# DPWM0 register map
Vendor: Texas Instruments
Peripheral module from a debugger description file (folder UCD3138R032RSM).
Registers are 32-bit, access per field, no defined reset value unless marked. A register's access mark holds for its fields unless they carry their own. Offsets are as the file gives them; lines under a group give offsets from that group; [hi:lo] are bit positions; {n}, {i} and the like mark numbered series; 'fields as' and 'values as' point back to an identical list; <NAME> marks a mode.

## DPWM0 — This is the MMR space for 1 instance of the DPWM
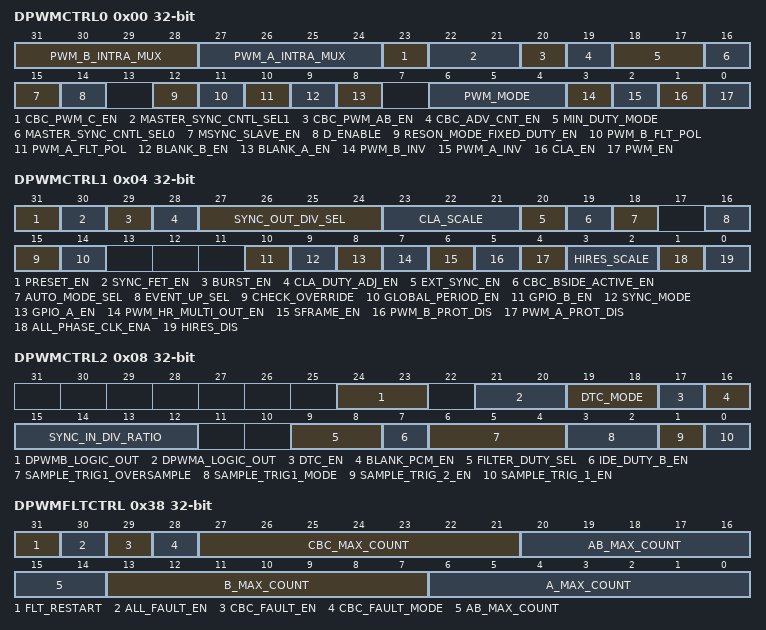
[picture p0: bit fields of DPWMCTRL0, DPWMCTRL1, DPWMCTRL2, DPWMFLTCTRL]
0x00 DPWMCTRL0 — DPWM Control Register 0
  [31:28] PWM_B_INTRA_MUX rw — Interchanges DPWM signals post edge generation
    8=n_3_C (Pass-through (DPWM n+3)C); 7=n_2_C (Pass-through (DPWM n+2)C); 6=n_1_C (Pass-through (DPWM n+1)C); 5=n_1_B (Pass-through (DPWM n+1)B); 4=n_1_A (Pass-through (DPWM n+1)A); 3=Crossover, this module; 2=PWM-C (PWM-C, this module); 1=Edge-gen output, this module; 0=Pass-through (Default)
  [27:24] PWM_A_INTRA_MUX rw — Combines DPWM signals are prior to HR module
    values as PWM_B_INTRA_MUX
  [23] CBC_PWM_C_EN rw — Sets if Fault CBC changes output waveform for PWM-C
    1=affected (PWM-C affected by Fault CBC); 0=unaffected (PWM-C unaffected by Fault CBC (Default))
  [22:21] MASTER_SYNC_CNTL_SEL1 rw — Master sync signal output selection when MASTER_SYNC_CNTL_SEL0=1
    2=CLA_DUTY_by_3 (Master sync output generated at CLA_DUTY/3 value); 1=CLA_DUTY_by_2 (Master sync output generated at CLA_DUTY/2 value); 0=CLA_PERIOD (Master sync output generated at CLA_PERIOD value (Default))
  [20] CBC_PWM_AB_EN rw — Sets if Fault CBC changes output waveform for PWM-A and PWM-B
    1=effected (PWM-A and PWM-B affected by Fault CBC); 0=unaffected (PWM-A and PWM-B unaffected by Fault CBC (Default))
  [19] CBC_ADV_CNT_EN rw — Selects cycle-by-cycle of operation
    1=effected (Normal Mode 1 = CBC enabled Multi and Resonant Modes 1 = PWM-A and PWM-B operate pulse matching enabled); 0=unaffected (Normal Mode 0 = CBC disabled (Default) Multi and Resonant Modes 0 = PWM-A and PWM-B operate independently (Default))
  [18:17] MIN_DUTY_MODE rw — Minimum Duty Cycle Mode
    2=calmped (= CLA value is clamped to MIN_DUTY_LOW register value when input value is less than MIN_DUTY_LOW); 1=calmped_zero (CLA value is clamped to zero when below input value is less than MIN_DUTY_LOW); 0=default (Suppression of minimum duty cycles is disabled (Default))
  [16] MASTER_SYNC_CNTL_SEL0 rw — Configures master sync location
    1=MASTER_SYNC_CNTL_SEL1 (Master Sync output controlled by MASTER_SYNC_CNTL_SEL1 bits); 0=Phase_Trigger_Register (Master Sync output controlled by Phase Trigger Register (Default))
  [15] MSYNC_SLAVE_EN rw — Multi-Sync Slave Mode Control
    1=Enable Multi-Sync Slave Mode, current channel will be slaved from corresponding channel; 0=default (PWM not synchronized to another PWM channel (Default))
  [14] D_ENABLE rw — Converts CLA duty value to DPWM as period-CLA duty value
    1=enable (Value used for event calculations is period minus CLA duty value); 0=default (Value used for event calculations if CLA Duty (Default))
  [12] RESON_MODE_FIXED_DUTY_EN rw — Configures how duty cycle is controlled in Resonance Mode
    1=SWITCH_HIGH (Resonant mode duty cycle set by Auto Switch High Register.); 0=default (Resonant mode duty cycle set by Filter duty (Default))
  [11] PWM_B_FLT_POL rw — Sets the fault output polarity during a disable condition (i.e. fault or module disabled)
    1=high (PWM B fault output polarity is set to high); 0=low (PWM B fault output polarity is set to low (Default))
  [10] PWM_A_FLT_POL rw — Sets the fault output polarity during a disable condition (i.e. fault or module disabled)
    1=high (PWM A fault output polarity is set to high); 0=low (PWM A fault output polarity is set to low (Default))
  [9] BLANK_B_EN rw — Comparator Blanking Window B Enable
    1=enabled (Comparator Blanking Window for PWM-B Enabled); 0=disabled (Comparator Blanking Window for PWM-B Disabled (Default))
  [8] BLANK_A_EN rw — Comparator Blanking Window A Enable
    1=enabled (Comparator Blanking Window for PWM-A Enabled); 0=disabled (Comparator Blanking Window for PWM-A Disabled (Default))
  [6:4] PWM_MODE rw — DPWM Mode
    4=Leading_mode; 2=MULTI_mode (Multi-Output Mode (Default)); 3=Triangular Mode; 1=Resonant Mode; 0=Normal Mode
  [3] PWM_B_INV rw — PWM B Output Polarity Control
    1=inverted (Inverts PWM B output); 0=Non-inverted PWM B output (Default)
  [2] PWM_A_INV rw — PWM A Output Polarity Control
    1=inverted (Inverts PWM A output); 0=Non-inverted PWM A output (Default)
  [1] CLA_EN rw — CLA Processing Enable
    1=Enable CLA input (Default); 0=Generate PWM waveforms from PWM Register values
  [0] PWM_EN rw — PWM Processing Enable
    1=Enable PWM operation; 0=Disable PWM module, outputs zero (Default)
0x04 DPWMCTRL1 — DPWM Control Register 1
  [31] PRESET_EN rw — Counter Preset Enable
    1=preset (Counter preset to Preset Count Value upon detection of sync); 0=reset (Counter reset to 0 upon detection of sync (Default))
  [30] SYNC_FET_EN rw — Counter Preset Enable
    1=enable (SyncFET Mode Enabled); 0=disable (SyncFET Mode Disabled (Default))
  [29] BURST_EN rw — Burst (Light Load) Mode Detection Enable
    1=enable (Burst Mode (Light Load) Detection enabled); 0=disable (Burst Mode (Light Load) Detection disabled (Default))
  [28] CLA_DUTY_ADJ_EN rw — Enables CLA Duty Adjust from Current/Flux Balancing
    1=enable (CLA Duty Adjust enabled); 0=disable (CLA Duty Adjust not enabled (Default))
  [27:24] SYNC_OUT_DIV_SEL rw — Sets the divider for generating the Sync Out pulse.Sync Out generated once every (n+1)switching cycles
    1=enable (Sync Out generated once every 2 switching cycles); 0=disable (Sync Out generated on every switching cycle (Default))
  [23:21] CLA_SCALE rw — Scaling for CLA Input Data
    6=CLA (CLA Value); 6=D_8 (CLA Value divided by 8); 5=M_8 (CLA Value multiplied by 8); 4=D_4 (CLA Value divided by 4); 3=M_4 (CLA Value multiplied by 4); 2=D_2 (CLA Value divided by 2); 1=M_2 (CLA Value multiplied by 2); 0=default (CLA Value (Default))
  [20] EXT_SYNC_EN rw — Slave DPWM to external sync
    1=sync (Slave DPWM to external sync); 0=not_sync (DPWM not synchronized to external sync (Default))
  [19] CBC_BSIDE_ACTIVE_EN rw — Sets if CBC responds to Fault CBC when PWM-B is active, only available in Multi and Reson modes
    1=sync (Response to Fault CBC when PWM-A or PWM-B active); 0=default (Response to Fault CBC when PWM-A active (Default))
  [18] AUTO_MODE_SEL rw — Auto Switching Mode Selec
    1=enabled (Auto Switching Mode enabled); 0=disabled (Auto Switching Mode disabled (Default))
  [16] EVENT_UP_SEL rw — Update End Period Mode
    0=anytime_update (Events updated anytime (Default)); 1=End_of_period_update (Events updated at End of Period)
  [15] CHECK_OVERRIDE rw — PWM Check Override
    1=b (Overrides checking for invalid configurations and turns off PWM mathematical checking functions (Default)); 0=a (DPWM checks mathematical settings within module, correct placement of Event settings/period settings. Invalid configurations are not allowed)
  [14] GLOBAL_PERIOD_EN rw — PWM Check Override
    1=GLOBAL (Event calculations use Global Period register); 0=DPWM (Event calculations use DPWM Period register (Default))
  [10] GPIO_B_EN rw — Enables GPIO mode for PWM B output
    1=GPIO (PWM B in GPIO mode); 0=DPWM (PWM B in DPWM mode (Default))
  [9] SYNC_MODE rw — Selects dynamic period adjustment based on sync input pulses
    1=Enabled (DPWM period register is updated dynamically based on SYNC input pulse width and DPWMPRD_SYNC_ADJ); 0=Disabled (DPWM period register is fixed and not updated dynamically (Default))
  [8] GPIO_A_EN rw — Enables GPIO mode for PWM A output
    1=GPIO (PWM A in GPIO mode); 0=DPWM (PWM A in DPWM mode (Default))
  [7] PWM_HR_MULTI_OUT_EN rw — Control bit for Hi-Res Block
    1=Enabled; 0=Disabled (Default)
  [6] SFRAME_EN rw — PWM Single Step Frame Mode Enable
    1== Enable Single Step Frame Mode. One EADC sample is requested, CLA then Filters, then one PWM duty cycle performed, then wait on Single Frame Trigger toggle before advancing to next frame.; 0=Disable Single Frame Mode (Default)
  [5] PWM_B_PROT_DIS rw — PWM B Asynchronous Protection Disable
    1=Disables asynchronous protection from turning off PWM B Output; 0=enable (Allows asynchronous protection to turn off PWM B Output (Default))
  [4] PWM_A_PROT_DIS rw — PWM A Asynchronous Protection Disable
    1=Disables asynchronous protection from turning off PWM A Output; 0=enable (Allows asynchronous protection to turn off PWM A Output (Default))
  [3:2] HIRES_SCALE rw — Determines resolution of high resolution steps
    3=PCLK_2 (Resolution of 2 phases. Full Resolution enabled.Resolution step = PCLK/2); 2=PCLK_4 (Resolution of 4 phases. Full Resolution enabled.Resolution step = PCLK/4); 1=PCLK_8 (Resolution of 8 phases. Full Resolution enabled.Resolution step = PCLK/8); 0=PCLK_16 (Resolution of 16 phases. Full Resolution enabled.Resolution step = PCLK/16)
  [1] ALL_PHASE_CLK_ENA rw — High Speed Oscillator Phase Enable
    1=enable_all (Enables all phases of high resolution clock from oscillator (Default)); 0=enable_required (Enables only required phases of clock when needed)
  [0] HIRES_DIS rw — PWM High Resolution Disable
    1=enable_all (Disable High Resolution logic); 0=enable_required (Enable High Resolution logic (Default))
0x08 DPWMCTRL2 — DPWM Control Register 2
  [24:23] DPWMB_LOGIC_OUT rw — Selection of final logic gating for DPWMB signal
    0=Mode0 (Passthrough (default)); 1=Mode1 (DPWMA (OR) DPWMB); 2=Mode2 (DPWMA (AND) DPWMB); 3=Mode3 (DPWM (XOR) DPWMB)
  [21:20] DPWMA_LOGIC_OUT rw — Selection of final logic gating for DPWMA signal
    values as DPWMB_LOGIC_OUT
  [19:18] DTC_MODE rw — DTC Mode Select
    0=DTC_phase_A (Only DTC phase adjust A utilized in edge adjustments (Default)); 1=DTC_phase_B (Only DTC phase adjust B utilized in edge adjustments); 2=DTC_phase_AB (Both DTC phase adjust A and B utilized in edge adjustments)
  [17] DTC_EN rw — Enables Dead Time Compensation Mode
    0=Disabled (Default); 1=Enabled
  [16] BLANK_PCM_EN rw — Comparator Blanking Window B Enable for PCM
    0=Disabled (Comparator Blanking A Window Disabled (Default)); 1=Enabled (Comparator Blanking A Window for PWM-B Enabled)
  [15:12] SYNC_IN_DIV_RATIO rw — Sets the number of syncs to be masked before a resync
  [9:8] FILTER_DUTY_SEL rw — Sets which register is sent to the Resonant Duty input of the Filter. Settings of 0 and 1 enable the 16 bit signed value of the Resonant Duty register to be added to the Filter Period value for period adjustment in resonant mode.
    0=PWM (PWM Period Register (Default)); 2=PWM Resonant Duty Register (Bits 13:0); 1=Event 2
  [7] IDE_DUTY_B_EN rw — IDE Duty Cycle Side B Enable
    1=enabled; 0== Disabled (Default)
  [6:4] SAMPLE_TRIG1_OVERSAMPLE rw — Oversample Select for Sample Trigger 1
    3=Eight (Trigger a EADC Sample at PWM Sample Trig Register value, and at PWM Sample Trig Register value by 7/8 and at PWM Sample Trig Register value by 6/8 and at PWM Sample Trig Register value by 5/8 and at PWM Sample Trig Register value by 4/8 and at PWM Sample Trig Register value by 3/8 and at PWM Sample Trig Register value by 2/8 and at PWM Sample Trig Register value by 1/8); 2=Four (Trigger a EADC Sample at PWM Sample Trig Register value, and at PWM Sample Trig Register value by 3/4 and at PWM Sample Trig Register value by 2/4 and at PWM Sample Trig Register value by 1/4); 1=Two (Trigger an EADC Sample at PWM Sample Trig Register value and at PWM Sample Trig Register value divided by 2); 0=default (Trigger an EADC Sample at PWM Sample Trig Register value (Default)); 4=Sixteen (Trigger a EADC Sample at PWM Sample Trig Register value, and at PWM Sample Trig Register value by 15/16 and at PWM Sample Trig Register value by 14/16 and at PWM Sample Trig Register value by 13/16 and at PWM Sample Trig Register value by 12/16 and at PWM Sample Trig Register value by 11/16 and at PWM Sample Trig Register value by 10/16 and at PWM Sample Trig Register value by 9/16 and at PWM Sample Trig Register value by 8/16 and at PWM Sample Trig Register value by 7/16 and at PWM Sample Trig Register value by 6/16 and at PWM Sample Trig Register value by 5/16 and at PWM Sample Trig Register value by 4/16 and at PWM Sample Trig Register value by 3/16 and at PWM Sample Trig Register value by 2/16 and at PWM Sample Trig Register value by 1/16); 5=ThirtyTwo (Trigger a EADC Sample at PWM Sample Trig Register value, and at PWM Sample Trig Register value by 31/32 and at PWM Sample Trig Register value by 30/32 and at PWM Sample Trig Register value by 29/32 and at PWM Sample Trig Register value by 28/32 and at PWM Sample Trig Register value by 27/32 and at PWM Sample Trig Register value by 26/32 and at PWM Sample Trig Register value by 25/32 and at PWM Sample Trig Register value by 24/32 and at PWM Sample Trig Register value by 23/32 and at PWM Sample Trig Register value by 22/32 and at PWM Sample Trig Register value by 21/32 and at PWM Sample Trig Register value by 20/32 and at PWM Sample Trig Register value by 19/32 and at PWM Sample Trig Register value by 18/32 and at PWM Sample Trig Register value by 17/32 and at PWM Sample Trig Register value by 16/32 and at PWM Sample Trig Register value by 15/32 and at PWM Sample Trig Register value by 14/32 and at PWM Sample Trig Register value by 13/32 and at PWM Sample Trig Register value by 12/32 and at PWM Sample Trig Register value by 11/32 and at PWM Sample Trig Register value by 10/32 and at PWM Sample Trig Register value by 9/32 and at PWM Sample Trig Register value by 8/32 and at PWM Sample Trig Register value by 7/32 and at PWM Sample Trig Register value by 6/32 and at PWM Sample Trig Register value by 5/32 and at PWM Sample Trig Register value by 4/32 and at PWM Sample Trig Register value by 3/32 and at PWM Sample Trig Register value by 2/32 and at PWM Sample Trig Register value by 1/32)
  [3:2] SAMPLE_TRIG1_MODE rw — Mode select for Sample Trigger 1
    3=mode2 (Trigger value is adaptive based on previous CBC location + Adaptive Offset); 2=mode1 (Trigger value is adaptive midpoint (EV1+CLA_DUTY/2 + Adaptive Offset) and uses previous CLA value at update event); 1=mode0 (Trigger value is adaptive midpoint (EV1+CLA_DUTY/2 + Adaptive Offset) and uses current CLA value at update event); 0=default (Trigger value is set using PWM Sample Trig Register value (Default))
  [1] SAMPLE_TRIG_2_EN rw — Sample Trigger 2 Enable
    1=enabled (Enable Sample Trigger 2); 0=disabled (Sample Trigger 2 Enable)
  [0] SAMPLE_TRIG_1_EN rw — Sample Trigger 1 Enable
    1=enabled (Enable Sample Trigger 1); 0=disabled (Sample Trigger 1 Enable)
0x0C DPWMPRD — DPWM Period Register
  [17:4] Period rw — PWM Period. Low resolution register, last 4 bits are read-only.
0x10 DPWMEV1 — DPWM Event 1 Register
  [17:4] EVENT1 rw — Configures the location of Event 1. Low resolution register, last 4 bits are unused
0x14 DPWMEV2 — DPWM Event 2 Register
  [17:0] EVENT2 rw — Configures the location of Event 2. Value equals number of PCLK clock periods in Bits 17:4 and number of high resolution clock phases of PCL in Bits 3:0 (dependent on Bits 3:2 of DPWM Control Register 2).
0x18 DPWMEV3 — DPWM Event 3 Register
  [17:0] EVENT3 rw — Configures the location of Event 3. Value equals number of PCLK clock periods in Bits 17:4 and number of high resolution clock phases of PCL in Bits 3:0
0x1C DPWMEV4 — DPWM Event 4 Register
  [17:0] EVENT4 rw — Configures the location of Event 4. Value equals number of PCLK clock periods in Bits 17:4 and number of high resolution clock phases of PCL in Bits 3:0
0x20 DPWMSAMPTRIG1 — DPWM Sample Trigger 1 Register
  [17:6] SAMPLE_TRIGGER rw — Configures the location of the sample trigger within a PWM period. Value equals the number of PCLK clock periods. Enables start of conversion for EADC. Low resolution register, last 6 bits are read-only
0x24 DPWMSAMPTRIG2 — DPWM Sample Trigger 2 Register
  [17:6] SAMPLE_TRIGGER rw — Configures the location of the sample trigger within a PWM period. Value equals the number of PCLK clock periods. Enables start of conversion for EADC. Low resolution register, last 6 bits are read-only.
0x28 DPWMPHASETRIG — DPWM Phase Trigger Register
  [17:4] PHASE_TRIGGER rw — Configures the phase trigger delay within multi-output mode. Value equals the number of PCLK clock periods. Low resolution register, last 4 bits are read-only
0x2C DPWMCYCADJA rw — DPWM Cycle Adjust A Register
  [15:0] CYCLE_ADJUST_A — Adjusts PWM A output signal. 16-bit signed number allows output signal to be delayed or sped up
0x30 DPWMCYCADJB rw — DPWM Cycle Adjust B Register
  [15:0] CYCLE_ADJUST_B — Adjusts PWM B output signal. 16-bit signed number allows output signal to be delayed or sped up
0x34 DPWMRESDUTY rw — DPWM Resonant Duty Register
  [13:0] RESONANT_DUTY — Controls the DPWM duty. 14-bit signed number is used as a Filter Output Multiplier in Resonant Mode
0x38 DPWMFLTCTRL rw — DPWM Fault Control Register
  [31] FLT_RESTART — Enables DPWM after Fault.
    1=enable (All DPWM Fault Modules enabled); 0=disable (All DPWM Fault Modules disabled (Default))
  [30] ALL_FAULT_EN — DPWM Fault Module enable
    1=enabled (All DPWM Fault Modules enabled); 0=diasbled (All DPWM Fault Modules disabled (Default))
  [29] CBC_FAULT_EN — Cycle by cycle Fault Enable
    1=enabled (DPWM to shut off as with any other fault); 0=shorten (Cycle by cycle just shortens DPWM pulses)
  [28] CBC_FAULT_MODE
    1=CBC_output (CBC Fault input set to output of CBC module); 0=raw_CBC (CBC Fault input set to raw CBC fault)
  [27:21] CBC_MAX_COUNT — ycle-by-Cycle Fault Count, sets the number of received sequential faults on Cycle by-Cycle Fault input before asserting the fault
  [20:14] AB_MAX_COUNT — Fault AB Count, sets the number of received sequential faults on Fault AB input before asserting the fault
  [13:7] B_MAX_COUNT — Fault B Count, sets the number of received sequential faults on Fault A input before asserting the fault
  [6:0] A_MAX_COUNT — Fault A Count, sets the number of received sequential faults on Fault A input before asserting the fault
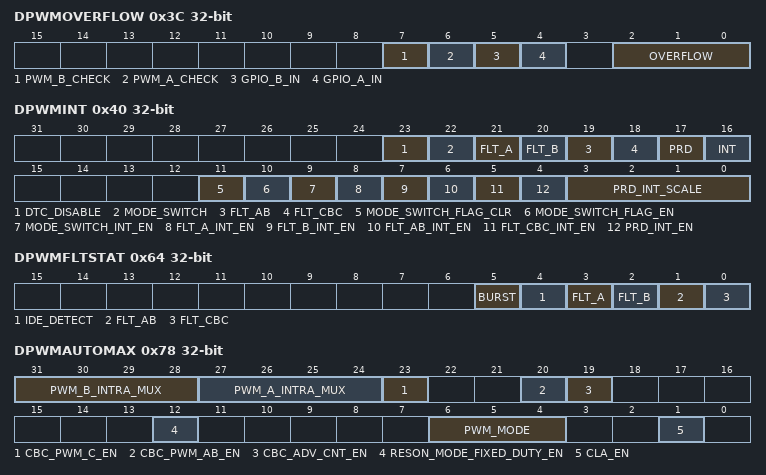
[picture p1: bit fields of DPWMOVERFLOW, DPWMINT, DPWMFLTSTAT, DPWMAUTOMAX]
0x3C DPWMOVERFLOW ro
  [7] PWM_B_CHECK — Value of PWM B internal check
    1=Failed checks (override required to enable output); 0=Passed checks
  [6] PWM_A_CHECK — Value of PWM A internal check
    values as PWM_B_CHECK
  [5] GPIO_B_IN — Value of PWM B input
    1=High signal on PWM B; 0=low (Low signal on PWM B)
  [4] GPIO_A_IN — Value of PWM A input
    1=High signal on PWM A; 0=low (Low signal on PWM A)
  [2:0] OVERFLOW — OVERFLOW[2] - CLA Event 4 Overflow Status 0 = PWM Event 4 has not overflowed 1 = Overflow condition found on PWM Event 4 OVERFLOW[1] - CLA Event 3 Overflow Status 0 = CLA Event 3 has not overflowed 1 = Overflow condition found on CLA Event 3 OVERFLOW[0] - CLA Event 2 Overflow Status 0 = CLA Event 2 has not overflowed 1 = Overflow condition found on CLA Event 2
0x40 DPWMINT — DPWM Interrupt Register
  [23] DTC_DISABLE ro — DTC Disabled Flag
    1=Set (Flag is set); 0=Not_asserted (Flag is not asserted)
  [22] MODE_SWITCH ro — Mode Switching Flag
    1=asserted (Flag is set); 0=not_asserted (Flag is not asserted)
  [21] FLT_A ro — Fault A Flag
    values as MODE_SWITCH
  [20] FLT_B ro — Fault B Flag
    values as MODE_SWITCH
  [19] FLT_AB ro — Fault AB Flag
    values as MODE_SWITCH
  [18] FLT_CBC ro — Fault Cycle-by-Cycle Flag
    values as MODE_SWITCH
  [17] PRD ro — PWM Period Interrupt Flag
    values as MODE_SWITCH
  [16] INT ro — Interrupt Out
    values as MODE_SWITCH
  [11] MODE_SWITCH_FLAG_CLR rw — Mode Switching Flag Clear
    1=Rising edge. 0-1 clears MODE_SWITCH bit; 0=default
  [10] MODE_SWITCH_FLAG_EN rw — Mode Switching Flag Enable
    1=Enables generation of flag for Mode Switching; 0=Disables generation of flag for Mode Switching (Default)
  [9] MODE_SWITCH_INT_EN rw — Mode Switching Interrupt Enable
    1=enable (Interrupt is enabled); 0=disable (Interrupt is not enabled (Default))
  [8] FLT_A_INT_EN rw — Fault A Flag Interrupt Enable
    values as MODE_SWITCH_INT_EN
  [7] FLT_B_INT_EN rw — Fault B Flag Interrupt Enable
    values as MODE_SWITCH_INT_EN
  [6] FLT_AB_INT_EN rw — Fault AB Flag Interrupt Enable
    values as MODE_SWITCH_INT_EN
  [5] FLT_CBC_INT_EN rw — Fault Cycle-by-Cycle Flag Interrupt Enable
    values as MODE_SWITCH_INT_EN
  [4] PRD_INT_EN rw — PWM Period Interrupt Enable
    1=Enables generation of periodic PWM interrupt; 0=Disables generation of periodic PWM interrupt (Default)
  [3:0] PRD_INT_SCALE rw — PWM Period Interrupt Enable
    15=switching_256 (Period Interrupt generated once every 256 switching cycle); 14=switching_224 (Period Interrupt generated once every 224 switching cycle); 13=switching_192 (Period Interrupt generated once every 192 switching cycle); 12=switching_160 (Period Interrupt generated once every 160 switching cycle); 11=switching_128 (Period Interrupt generated once every 128 switching cycle); 10=switching_96 (Period Interrupt generated once every 128 switching cycle); 9=switching_80 (Period Interrupt generated once every 80 switching cycle); 8=switching_64 (Period Interrupt generated once every 64 switching cycle); 7=switching_48 (Period Interrupt generated once every 48 switching cycle); 6=switching_32 (Period Interrupt generated once every 32 switching cycle); 5=switching_16 (Period Interrupt generated once every 16 switching cycle); 4=switching_8 (Period Interrupt generated once every 8 switching cycle); 3=switching_6 (Period Interrupt generated once every 6 switching cycle); 2=switching_4 (Period Interrupt generated once every 4 switching cycle); 1=switching_2 (Period Interrupt generated once every 2 switching cycle); 0=switching_1 (Period Interrupt generated every switching cycle (Default))
0x44 DPWMCNTPRE — DPWM Counter Preset Register
  [17:4] PRESET rw — Counter preset value, counter reset to this value upon detection of sync when PRESET_EN bit in DPWMCTRL2 is enabled. Low resolution register, last 4 bits are read-only.
0x48 DPWMBLKABEG — DPWM Blanking A Begin Register
  [17:4] BLANK_A_BEGIN rw — Configures start of Comparator Blanking Window A. Low resolution register, last 4 bits are read-only
0x4C DPWMBLKAEND — DPWM Blanking A End Register
  [17:4] BLANK_A_END rw — Configures end of Comparator Blanking Window A. Low resolution register, last 4 bits are read-only.
0x50 DPWMBLKBBEG — DPWM Blanking B Begin Register
  [17:4] BLANK_B_BEGIN rw — Configures start of Comparator Blanking Window B. Low resolution register, last 4 bits are read-only. Can also define the start of the DPWMC pulse.
0x54 DPWMBLKBEND — DPWM Blanking B End Register
  [17:4] BLANK_B_END rw — Configures end of Comparator Blanking Window B. Low resolution register, last 4 bits are read-only. Can also define the end of the DPWMC pulse
0x58 DPWMMINDUTYHI — DPWM Minimum Duty Cycle High Register
  [17:4] MIN_DUTY_HIGH rw — Configures upper threshold for minimum duty cycle logic. Low resolution register, last 4 bits are read-only
0x5C DPWMMINDUTYLO — DPWM Minimum Duty Cycle Low Register
  [17:4] MIN_DUTY_LOW rw — Configures lower threshold for minimum duty cycle logic. Low resolution register, last 4 bits are read-only
0x60 DPWMADAPTIVE rw — DPWM Adaptive Sample Register
  [11:0] ADAPT_SAMP — Configures Adaptive Sample Adjust
0x64 DPWMFLTSTAT ro — DPWM Fault Status
  [5] BURST — Burst Mode Detection Status
    1=asserted (Burst Mode Detection is set); 0=not_asserted (Burst Mode Detection is not asserted)
  [4] IDE_DETECT — IDE Detection Status (from Analog Comparators)
    1=asserted (IDE Detection is se); 0=not_asserted (IDE Detection is not asserted)
  [3] FLT_A — Fault A Detection Status
    1=asserted (Fault A Detection is set); 0=not_asserted (Fault A Detection is not asserted)
  [2] FLT_B — Fault B Detection Status
    1=asserted (Fault B Detection is set); 0=not_asserted (Fault B Detection is not asserted)
  [1] FLT_AB — Fault AB Detection Status
    1=asserted (Fault AB Detection is set); 0=not_asserted (Fault AB Detection is not asserted)
  [0] FLT_CBC — Current Limit Detection Status
    1=asserted (Current Limit Detection is set); 0=not_asserted (Current Limit Detection is not asserted)
0x68 DPWMAUTOSWHIUPTHRESH — DPWM Auto Switch High Upper Thresh Register
  [17:4] AUTO_SWITCH_HIGH_UPPER rw — Configures upper threshold for Auto Switch Mode High operation. Mode switching does not occur between Auto Switch High Upper and Auto Switch High Lower thresholds. Low resolution register, last 4 bits are read-only
0x6C DPWMAUTOSWHILOWTHRESH — DPWM Auto Switch High Upper Thresh Register
  [17:4] AUTO_SWITCH_HIGH_LOWER rw — Configures lower threshold for Auto Switch Mode High operation. Mode switching does not occur between Auto Switch High Upper and Auto Switch High Lower thresholds. Low resolution register, last 4 bits are read-only.
0x70 DPWMAUTOSWLOUPTHRESH — DPWM Auto Switch Low Upper Thresh Register
  [17:4] AUTO_SWITCH_LOW_UPPER rw — Configures UPPER threshold for Auto Switch Mode High operation. Mode switching does not occur between Auto Switch Low Upper and Auto Switch Low Lower thresholds. Low resolution register, last 4 bits are read-only.
0x74 DPWMAUTOSWLOLOWTHRESH — DPWM Auto Switch Low Lower Thresh Register
  [17:4] AUTO_SWITCH_LOW_LOWER rw — Configures lower threshold for Auto Switch Mode Low operation. Mode switching does not occur between Auto Switch Low Upper and Auto Switch Low Lower thresholds. Low resolution register, last 4 bits are read-only
0x78 DPWMAUTOMAX — DPWM Auto Config Max Register
  [31:28] PWM_B_INTRA_MUX rw — Interchanges DPWM signals post edge generation
    8=N_3_C (Pass-through (DPWM n+3)C); 7=N_2_C (Pass-through (DPWM n+2)C); 6=N_1_C (Pass-through (DPWM n+1)C); 5=N_1_B (Pass-through (DPWM n+1)B); 4=N_1_A (Pass-through (DPWM n+1)A); 3=Crossover, this module; 2=PWM_C (PWM-C, this module); 1=Edge-gen output, this module; 0=default (Pass-through (Default))
  [27:24] PWM_A_INTRA_MUX rw — Combines DPWM signals are prior to HR module
    values as PWM_B_INTRA_MUX
  [23] CBC_PWM_C_EN rw — Sets if Fault CBC changes output waveform for PWM-C
    1=effected (PWM-C affected by Fault CBC); 0=unaffected (PWM-C unaffected by Fault CBC (Default))
  [20] CBC_PWM_AB_EN rw — Sets if Fault CBC changes output waveform for PWM-A and PWM-B
    values as DPWMCTRL0.CBC_PWM_AB_EN
  [19] CBC_ADV_CNT_EN rw — Selects cycle-by-cycle of operation Normal Mode 0 = CBC disabled (Default) 1 = CBC enabled Multi and Resonant Modes 0 = PWM-A and PWM-B operate independently (Default) 1 = PWM-A and PWM-B pulse matching enabled
  [12] RESON_MODE_FIXED_DUTY_EN rw — Configures how duty cycle is controlled in Resonance Mode
    1=effected (Resonant mode duty cycle set by Auto Switch High Register); 0=default (Resonant mode duty cycle set by Filter duty (Default))
  [6:4] PWM_MODE rw — DPWM Mode
    4=Leading Mode; 3=Triangular Mode; 2=Multi-Output Mode; 1=Resonant Mode; 0=Normal Mode (Default)
  [1] CLA_EN rw — CLA Processing Enable
    1=effected (Enable CLA input); 0=default (Generate PWM waveforms from PWM Register values (Default))
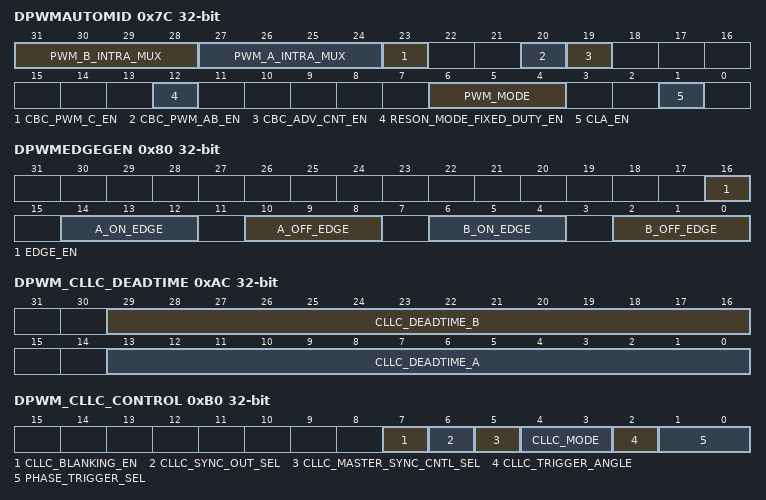
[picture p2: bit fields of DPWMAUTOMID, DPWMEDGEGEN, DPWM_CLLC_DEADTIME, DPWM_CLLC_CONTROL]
0x7C DPWMAUTOMID — DPWM Auto Config Mid Register
  fields as DPWMAUTOMAX
0x80 DPWMEDGEGEN — DPWM Edge PWM Generation Control Register
  [16] EDGE_EN rw — Enables edge generate module. When combining dpwm's, all modules must have this bit enabled
  [14:12] A_ON_EDGE rw — Select input edge to trigger A ON output edge
    7=Below_B_neg (Below (n+1) DPWM negedge A); 6=Below_B_pos (Below (n+1) DPWM posedge B); 5=Below_A_neg (Below (n+1) DPWM negedge A); 4=Below_A_pos (Below (n+1) DPWM posedge A); 3=Current_B_neg (Current DPWM negedge B); 2=Current_B_pos (Current DPWM posedge B); 1=Current_A_neg (Current DPWM negedge A); 0=Current_A_pos (Current DPWM posedge A)
  [10:8] A_OFF_EDGE rw — Select input edge to trigger A OFF output edge
    values as A_ON_EDGE
  [6:4] B_ON_EDGE rw — Select input edge to trigger B ON output edge
    values as A_ON_EDGE
  [2:0] B_OFF_EDGE rw — Select input edge to trigger B OFF output edge
    values as A_ON_EDGE
0x84 DPWMFILTERDUTYREAD ro
  [17:0] FILTER_DUTY — Filter Duty value received by DPWM Module
0x88 DPWMCBCLOCATION ro
  [13:0] CBC_LOCATION — Holds counter value of last CBC event.
0x8C DPWMPER_SYNC_ADJ — DPWM Period Sync Adjust Register
  [9:0] DPWMPER_SYNC_ADJ rw — DPWM period addition (tsync) for SYNC_MODE=1b (resolution =2.5ns)
0x90 DPWMBISTSTAT ro — DPWM BIST Status Register
  [14:0] BIST_CNT — BIST Count accumulated during BIST test.
0x94 DPWM_CLLC_MIN_HALF_PRD — DPWM CLLC Minimum Half Period Register
  [13:0] CLLC_MIN_HALF_PRD rw — Configures the CLLC Minimum Half Period.
0x98 DPWM_CLLC_MAX_HALF_PRD — DPWM CLLC Maximum Half Period Register
  [13:0] CLLC_MAX_HALF_PRD rw — Configures the CLLC Maximum Half Period.
0x9C DPWM_CLLC_MAX_ON_TIME — DPWM CLLC Maximum ON Time for the PWM pulse
  [13:0] CLLC_MAX_ON_TIME rw — Configures the CLLC Maximum ON Time for the PWM pulse.
0xA0 DPWM_CLLC_PHASE_SHIFT — DPWM CLLC PHASE SHIFT Trigger value
  [13:0] CLLC_PHASE_SHIFT rw — Configures the CLLC Trigger value.
0xA4 DPWM_CLLC_NEG_PHASE_SHIFT — DPWM CLLC Trigger value in Negative phase
  [13:0] CLLC_NEG_PHASE_SHIFT rw — Configures the CLLC Trigger value in Negative phase.
0xA8 DPWM_CLLC_POS_PHASE_SHIFT — DPWM CLLC Trigger value in Positive phase
  [13:0] CLLC_POS_PHASE_SHIFT rw — Configures the CLLC Trigger value in Positive phase.
0xAC DPWM_CLLC_DEADTIME — DPWM CLLC Deadtime between A and B edges
  [29:16] CLLC_DEADTIME_B rw — Configures the CLLC Deadtime on B edges.
  [13:0] CLLC_DEADTIME_A rw — Configures the CLLC Deadtime on A edges.
0xB0 DPWM_CLLC_CONTROL
  [7] CLLC_BLANKING_EN rw — Enables Blanking on DPWMA in CLLC mode.
    1=Enabled (Blanking window is enabled on DPWMA in CLLC mode.); 0=Disabled (Blanking window is disabled on DPWMA in CLLC mode (Default))
  [6] CLLC_SYNC_OUT_SEL rw — Selects the trigger signal to be sent to SYNC pin. LOOPMUX.SYNCCTRL need to be configured to select the DPWM source for the SYNC pin output signal. in CLLC mode.
    1=ANGLE_PHASE_SHIFT (Triggers at phase shift value given in DPWM_CLLC_NEG_PHASE_SHIFT register (for TRIGGERED_BOFF_PERIOD mode) or DPWM_CLLC_POS_PHASE_SHIFT register (for all other modes) in CLLC mode.); 0=PHASE_TRIGGER (Triggers at phase shift value configured in DPWM_CLLC_PHASE_SHIFT register and PHASE_TRIGGER_SEL bit of DPWM_CLLC_CONTROL register (default))
  [5] CLLC_MASTER_SYNC_CNTL_SEL rw — Configures the internal sync signal output to trigger other DPWMs in CLLC mode.
    values as CLLC_SYNC_OUT_SEL
  [4:3] CLLC_MODE rw — Configures the CLLC Mode.
    3=Resonant_mode; 2=Max_on_time_Freq_mod (Max_on_time and frequency modulation); 1=Max_on_time_Max_period (Max_on_time and max period mode); 0=Max period mode. (Default)
  [2] CLLC_TRIGGER_ANGLE rw — Configures the CLLC Trigger Angle.
    1=FALL (Trigger generated during the Falling phase of the PWM counter.); 0=RISE (Trigger generated during the Rising phase of the PWM counter (Default))
  [1:0] PHASE_TRIGGER_SEL rw — Decides the Phase Trigger value to be used.
    3=MAX_PERIOD_COUNT_60DEG_PHASE_SHIFT (Trigger generated at 60 degrees of the maximum period count.); 1=MAX_PERIOD_COUNT_120DEG_PHASE_SHIFT (Trigger generated at 120 degrees of the maximum period count.); 2=MAX_PERIOD_COUNT_90DEG_PHASE_SHIFT (Trigger generated at 90 degrees of the maximum period count.); 0=CLLC_PHASE_SHIFT_SEL (Phase Trigger register value used to generate trigger (Default))
0xB4 DPWM_CLLC_BLANKING_BEGIN — DPWM CLLC Blanking A Begin Register
  [13:0] CLLC_BLANK_A_BEGIN rw — Configures start of Comparator Blanking Window A in CLLC mode.
0xB8 DPWM_CLLC_BLANKING_END — DPWM CLLC Blanking A End Register
  [13:0] CLLC_BLANK_A_END rw — Configures end of Comparator Blanking Window A in CLLC mode.
0xBC DPWM_CLLC_SLAVE_SEL — DPWM CLLC Slave select Register
  [2:0] CLLC_SLAVE_SEL rw — Configures DPWM Slave selection in CLLC mode.
    7=Master (Selects the DPWM instance as master (Default)); {v}=DPWM{v} (Select the DPWM{v} as slave in CLLC mode) (v=0..3)
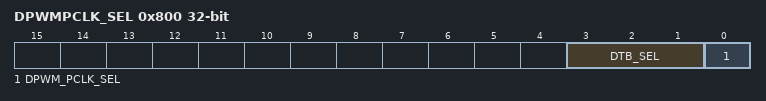
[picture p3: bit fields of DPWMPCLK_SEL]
0x800 DPWMPCLK_SEL — DPWM PCLK Select Register (INTERNAL USE ONLY)
  [3:1] DTB_SEL rw — Digital Test bus selection
  [0] DPWM_PCLK_SEL rw — DPWM PCLK Select
    1=MCLK (Select MCLK clock for PCLK input port); 0=PCLK (Select the PCLK clock for PCLK input port (Default))
